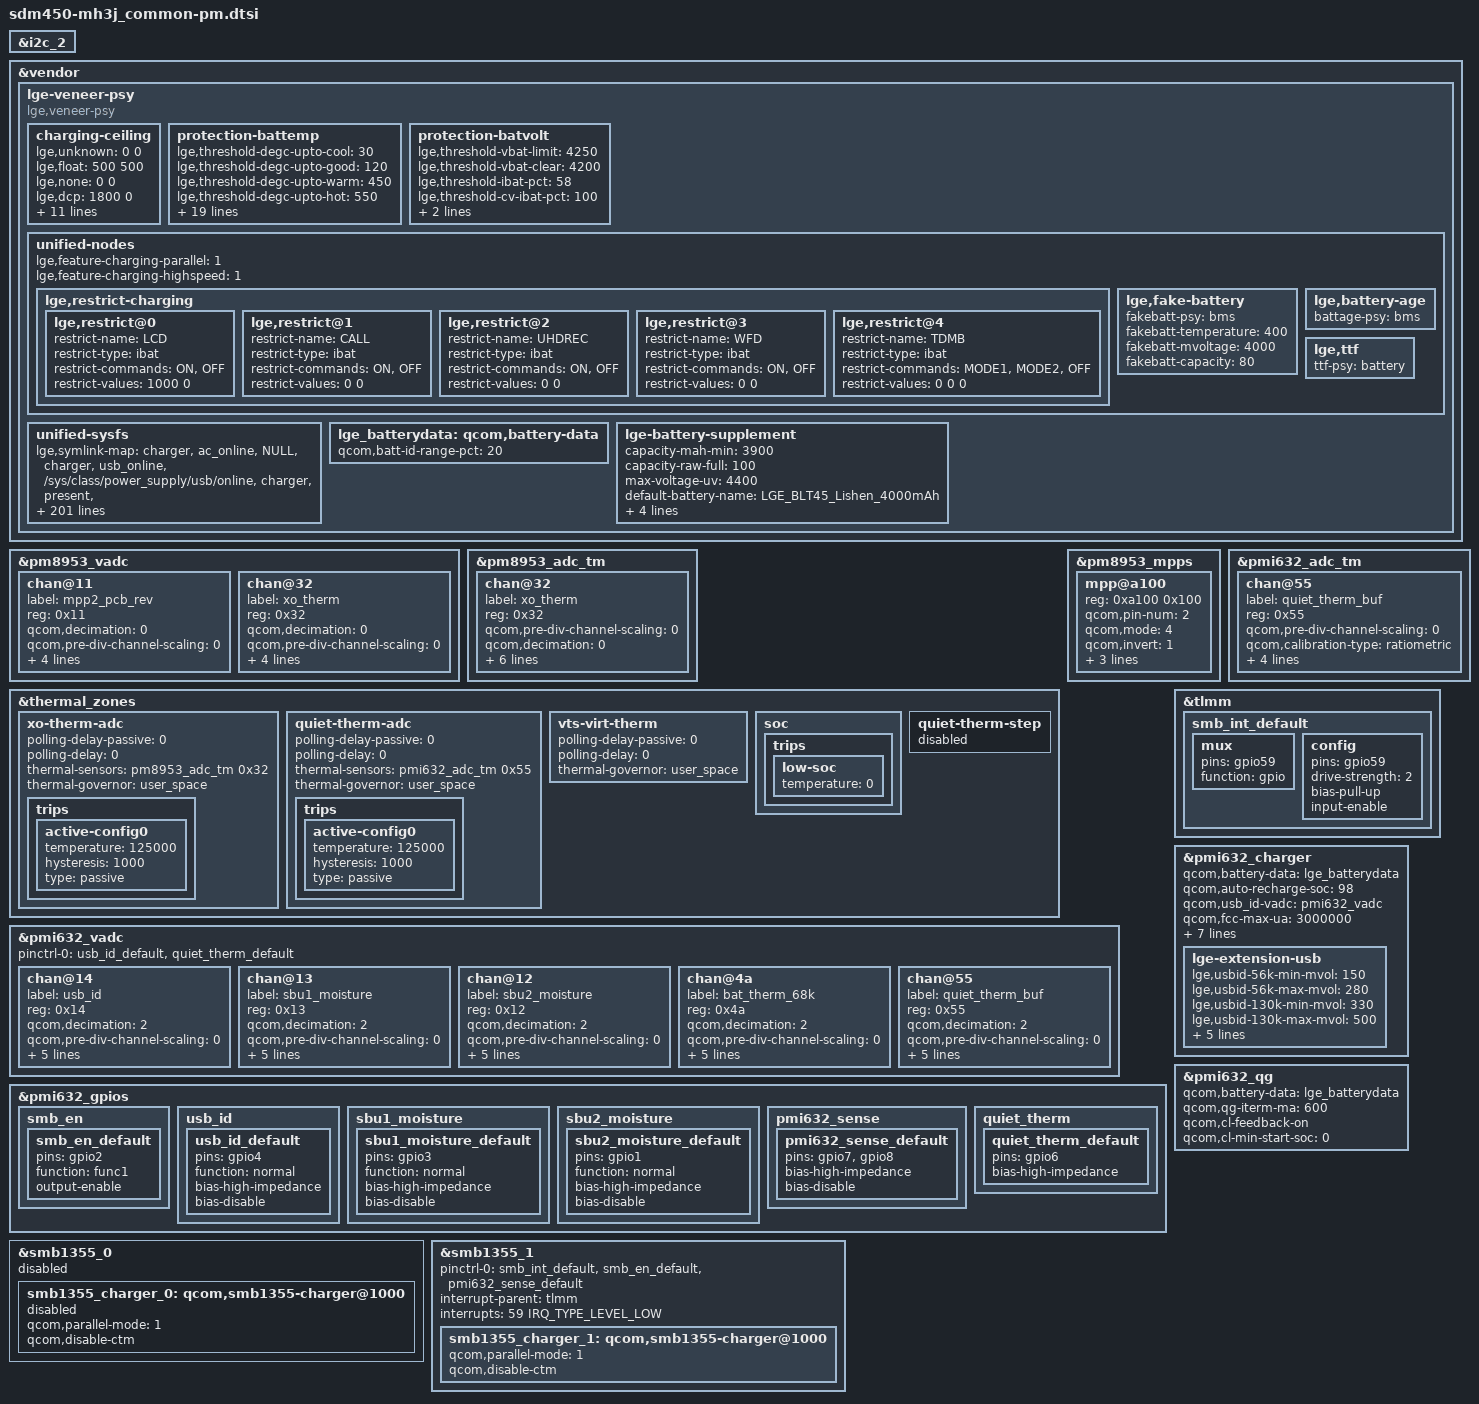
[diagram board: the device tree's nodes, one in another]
/*
 * Copyright (c) 2018, The Linux Foundation. All rights reserved.
 *
 * This program is free software; you can redistribute it and/or modify
 * it under the terms of the GNU General Public License version 2 and
 * only version 2 as published by the Free Software Foundation.
 *
 * This program is distributed in the hope that it will be useful,
 * but WITHOUT ANY WARRANTY; without even the implied warranty of
 * MERCHANTABILITY or FITNESS FOR A PARTICULAR PURPOSE.  See the
 * GNU General Public License for more details.
 */

&i2c_2 {
#include "../../../qcom/smb1355.dtsi"
};

&vendor {
    lge-veneer-psy {
        compatible = "lge,veneer-psy";
        status = "ok";

        charging-ceiling {
            /*             iusb ibat  : 0 means UNCEILING */
            lge,unknown = <   0    0>;
            lge,float   = < 500  500>;
            lge,none    = <   0    0>;

            lge,dcp     = <1800    0>;
            lge,10k     = <3000    0>;
            lge,22k     = <1500    0>;
            lge,qc2     = <1800    0>;
            lge,qc3     = <1800    0>;

            lge,usb2    = < 500    0>;
            lge,usb3    = < 900    0>;
            lge,cdp     = <1500 1500>;
            lge,pd      = <   0    0>;

            lge,56k     = <1500  500>;
            lge,130k    = <1500  500>;
            lge,910k    = <1500  500>;
        };

        protection-battemp {
            lge,threshold-degc-upto-cool = <30>;
            lge,threshold-degc-upto-good = <120>;
            lge,threshold-degc-upto-warm = <450>;
            lge,threshold-degc-upto-hot = <550>;
            lge,threshold-degc-downto-warm = <520>;
            lge,threshold-degc-downto-good = <430>;
            lge,threshold-degc-downto-cool = <100>;
            lge,threshold-degc-downto-cold = <0>;

            lge,period-ms-emergency = <10000>;
            lge,period-ms-warning   = <30000>;
            lge,period-ms-normal    = <60000>;

            // parameters for warning status cool and warm
            lge,cool-mv-alert   = <4000>;
            lge,cool-ma-alert   = <500>;    // fixed 500 mA
            lge,cool-ma-pct     = <30>;     // means 0.3C rate

            lge,warm-mv-float   = <4000>;
            lge,warm-ma-pct     = <30>;     // means 0.3C rate

            // parameters for battery protection at chilly status
            lge,chilly-status-support;
            lge,chilly-degc-lowerbound = <0>;
            lge,chilly-degc-upperbound = <150>;
            lge,chilly-mv-alert    = <4000>;
            lge,chilly-mv-bound     = <200>;
            lge,chilly-ma-alert    = <630>;
            lge,chilly-ma-pct      = <50>;  // means 0.5C rate under batvol 4V
        };

        protection-batvolt {
            lge,threshold-vbat-limit = <4250>;
            lge,threshold-vbat-clear = <4200>;
	    lge,threshold-ibat-pct = <58>;	// means 0.6C rate
	    lge,threshold-cv-ibat-pct = <100>;	// means 0.1C rate

            lge,step-ibat-ma = <100>;
            lge,step-poll-ms = <5000>;
        };

        unified-nodes {
            lge,feature-charging-parallel = <1>;
            lge,feature-charging-highspeed = <1>;

            lge,restrict-charging {
                // restrict-values 0 means UNCEILING

                lge,restrict@0 {
                    restrict-name = "LCD";
                    restrict-type = "ibat";
                    restrict-commands = "ON", "OFF";
                    restrict-values = <1000      0>;
                };
                lge,restrict@1 {
                    restrict-name = "CALL";
                    restrict-type = "ibat";
                    restrict-commands = "ON", "OFF";
                    restrict-values = < 0      0>;
                };
                lge,restrict@2 {
                    restrict-name = "UHDREC";
                    restrict-type = "ibat";
                    restrict-commands = "ON", "OFF";
                    restrict-values = < 0      0>;
                };
                lge,restrict@3 {
                    restrict-name = "WFD";
                    restrict-type = "ibat";
                    restrict-commands = "ON", "OFF";
                    restrict-values = < 0      0>;
                };
                lge,restrict@4 {
                    restrict-name = "TDMB";
                    restrict-type = "ibat";
                    restrict-commands = "MODE1", "MODE2", "OFF";
                    restrict-values = <    0      0      0>;
                };
            };

            lge,fake-battery {
                fakebatt-psy = "bms";       // What 'psy' does implement(or support) the fake battery?
                fakebatt-temperature = <400>;
                fakebatt-mvoltage = <4000>;
                fakebatt-capacity = <80>;
            };

            lge,battery-age {
                battage-psy = "bms";        // What 'psy' does implement(or support) the battery age?
            };

            lge,ttf {
                ttf-psy = "battery";	// What 'psy' does implement(or support) the time to full now?
            };
        };

        unified-sysfs {
            lge,symlink-map =
                /* group , user_node, kernel node */
                /* Charger */
                "charger",                     "ac_online", "NULL",
                "charger",                    "usb_online", "/sys/class/power_supply/usb/online",   /* TODO */
                "charger",                       "present", "/sys/class/power_supply/usb/present",
                "charger",                    "wlc_online", "/sys/class/power_supply/wireless/online",
                "charger",                          "type", "/sys/class/power_supply/usb/real_type",
		"charger",                   "usb_pd_type", "/sys/class/power_supply/usb/real_type",
                "charger",                      "time_out", "/sys/class/power_supply/battery/safety_timer_enabled",
                "charger",              "charging_enabled", "/sys/devices/platform/lge-unified-nodes/charging_enable",
                "charger",                  "ibat_current", "/sys/class/power_supply/battery/current_now",
                "charger",                  "ichg_current", "/sys/class/power_supply/usb/current_max",
                "charger",                  "iusb_control", "NULL",
                "charger",            "thermal_mitigation", "NULL",
                "charger",        "wlc_thermal_mitigation", "NULL",
                "charger",       "usb_parallel_chg_status", "NULL",
                "charger", "usb_parallel_charging_enabled", "/sys/class/power_supply/parallel/charging_enabled",
                "charger", "factory_parallel_charger_test", "/sys/devices/platform/lge-unified-nodes/support_fastpl",
                "charger",            "moisture_detection", "/sys/class/power_supply/usb/moisture_detected",
                "charger",           "restricted_charging", "/sys/devices/platform/lge-unified-nodes/charging_restriction",
                "charger",              "ibat_max_current", "/sys/class/power_supply/battery/constant_charge_current_max",
                "charger",                       "chgstep", "/sys/devices/platform/lge-unified-nodes/charging_step",
                "charger",               "connection_type", "NULL",
                "charger",                       "fastchg", "/sys/devices/platform/lge-unified-nodes/charger_highspeed",
                "charger",         "input_current_settled", "/sys/class/power_supply/usb/input_current_settled",
                "charger",             "input_current_max", "/sys/class/power_supply/usb/input_current_settled",
                "charger",            "store_demo_enabled", "NULL",
                "charger",     "wireless_charging_enabled", "NULL",
                "charger",                 "input_suspend", "/sys/class/power_supply/battery/input_suspend",
                "charger",                  "incompatible", "/sys/devices/platform/lge-unified-nodes/charger_incompatible",
                "charger",                    "hvdcp_fake", "/sys/devices/platform/lge-unified-nodes/fake_hvdcp",
                "charger",               "usb_current_max", "/sys/devices/platform/lge-unified-nodes/fake_sdpmax",
                "charger",               "fastchg_support", "/sys/devices/platform/lge-unified-nodes/support_fastchg",
                "charger",                    "usbid_type", "/sys/class/power_supply/usb/resistance_id",
                "charger",                 "ccd_batchg_en", "/sys/devices/platform/lge-unified-nodes/ccd_batchg_en",
                "charger",             "ccd_input_suspend", "/sys/devices/platform/lge-unified-nodes/ccd_input_suspend",
                "charger",                       "ccd_icl", "/sys/devices/platform/lge-unified-nodes/ccd_icl",
                "charger",                       "ccd_fcc", "/sys/devices/platform/lge-unified-nodes/ccd_fcc",
                "charger",                    "ccd_vfloat", "/sys/devices/platform/lge-unified-nodes/ccd_vfloat",
		"charger",                     "aicl_done", "/sys/devices/platform/lge-unified-nodes/aicl_done",
                /* ADC/MPP */
                "adc",              "thermal", "/sys/class/thermal/",
                "adc",             "xo_therm", "/sys/class/hwmon/hwmon1/device/xo_therm",
                "adc",           "batt_therm", "/sys/class/power_supply/battery/temp",
                "adc",              "batt_id", "/sys/devices/platform/lge-unified-nodes/battery_valid",
                "adc",            "pa_therm0", "/sys/class/hwmon/hwmon1/device/pa_therm0",
                "adc",            "pa_therm1", "NULL",
                "adc",           "quiet_therm","/sys/class/hwmon/hwmon2/device/quiet_therm_buf",
                "adc",               "usb_in", "/sys/class/power_supply/usb/voltage_now",
                "adc",                "vcoin", "/sys/class/hwmon/hwmon2/device/vcoin",
                "adc",              "vph_pwr", "/sys/class/hwmon/hwmon2/device/vph_pwr",
                "adc",               "usb_id", "/sys/devices/platform/lge-unified-nodes/charger_usbid",
                "adc",             "usb_edge", "NULL",
                "adc",                 "pmic", "/sys/class/thermal/thermal_zone2/temp",
                "adc",                  "vts", "/sys/bus/platform/drivers/monitor-thermal/soc:lge,monitor-thermal/vts_temp",
                /* Battery */
                "battery",         "capacity", "/sys/class/power_supply/battery/capacity",
                "battery",           "health", "/sys/class/power_supply/battery/health",
                "battery",          "present", "/sys/class/power_supply/battery/present",
                "battery",      "pseudo_batt", "/sys/devices/platform/lge-unified-nodes/fake_battery",
                "battery",           "status", "/sys/class/power_supply/battery/status",
                "battery",       "status_raw", "NULL",
                "battery",             "temp", "/sys/class/power_supply/battery/temp",
                "battery",    "valid_batt_id", "/sys/devices/platform/lge-unified-nodes/battery_valid",
                "battery",      "voltage_now", "/sys/class/power_supply/battery/voltage_now",
                "battery",          "vzw_chg", "/sys/devices/platform/lge-unified-nodes/charger_verbose",
                "battery",     "raw_capacity", "/sys/class/power_supply/bms/capacity",
                "battery",        "condition", "/sys/devices/platform/lge-unified-nodes/battery_condition",
                "battery",      "battery_age", "/sys/devices/platform/lge-unified-nodes/battery_age",
                "battery","battery_age_level", "/sys/devices/platform/lge-unified-nodes/battery_age",
                "battery",            "cycle", "/sys/class/power_supply/bms/cycle_count",
                "battery",     "battery_type", "/sys/class/power_supply/bms/battery_type",
                "battery",      "charge_full", "/sys/class/power_supply/bms/charge_full",
                "battery",   "charge_now_raw", "/sys/class/power_supply/bms/charge_now_raw",
                "battery",     "ttf_capacity", "/sys/devices/platform/lge-unified-nodes/ttf_capacity",
                "battery", "time_to_full_now", "/sys/devices/platform/lge-unified-nodes/time_to_full_now",
                /* LCD Backlight */
                "lcd",           "brightness", "/sys/class/backlight/panel0-backlight/brightness",
                "lcd",       "max_brightness", "/sys/class/backlight/panel0-backlight/max_brightness",
                "lcd_ex",        "brightness", "NULL",
                "lcd_ex",    "max_brightness", "NULL",
                /* KEY LED */
                "key_led",   "red_brightness", "/sys/class/leds/red/brightness",
                "key_led", "green_brightness", "/sys/class/leds/green/brightness",
                "key_led",  "blue_brightness", "/sys/class/leds/blue/brightness",
                "key_led",  "setting",         "/sys/class/lg_rgb_led/use_patterns/setting",
                /* CPU */
                "cpu",       "cpu_idle_modes", "NULL",
                /* GPU */
                "gpu",                 "busy", "/sys/class/kgsl/kgsl-3d0/gpubusy",
                "gpu",               "gpuclk", "/sys/class/kgsl/kgsl-3d0/gpuclk",
                /* PLATFORM */
                "platform",       "speed_bin", "NULL",
                "platform",         "pvs_bin", "NULL",
                "platform",     "power_state", "/sys/power/autosleep",
                "platform",   "poweron_alarm", "/sys/module/qpnp_rtc/parameters/poweron_alarm",
                "platform",         "pcb_rev", "/sys/class/hwmon/hwmon1/device/mpp2_pcb_rev",
                "platform",       "smpl_boot", "/sys/module/lge_smpl_count/parameters/smpl_boot",
                /* testmode */
                "testmode",            "temp", "/sys/class/power_supply/battery/temp",
                "testmode",     "voltage_now", "/sys/class/power_supply/battery/voltage_now",
                "testmode",          "usb_id", "/sys/devices/platform/lge-unified-nodes/charger_usbid",
                "testmode",         "batt_id", "/sys/devices/platform/lge-unified-nodes/battery_valid",
                "testmode",         "fuelval", "/sys/class/power_supply/battery/capacity",
                "testmode",        "xo_therm", "/sys/class/hwmon/hwmon1/device/xo_therm",
                "testmode",          "charge", "/sys/class/power_supply/battery/battery_charging_enabled",
                "testmode",          "chcomp", "/sys/devices/platform/lge-unified-nodes/charging_completed",
                "testmode",           "usbin", "/sys/class/power_supply/usb/voltage_now",
                "testmode",       "pa_therm0", "/sys/class/hwmon/hwmon1/device/pa_therm0",
                "testmode",       "pa_therm1", "NULL",
                "testmode",       "bd_therm2", "/sys/class/hwmon/hwmon2/device/quiet_therm_buf",
                "testmode",           "vcoin", "/sys/class/hwmon/hwmon2/device/vcoin",
                "testmode",         "vph_pwr", "/sys/class/hwmon/hwmon2/device/vph_pwr",
                "testmode",     "current_now", "/sys/class/power_supply/battery/current_now",
                "testmode",     "current_max", "/sys/class/power_supply/usb/current_max",
                "testmode",         "pcb_rev", "/sys/class/hwmon/hwmon1/device/mpp2_pcb_rev",
                "testmode",      "chgmodeoff", "/sys/class/power_supply/battery/input_suspend",
                "testmode",         "fuelrst", "/sys/class/power_supply/battery/present",
                "testmode",        "rtc_time", "/dev/rtc0",
                "testmode",           "pmrst", "NULL",
                "testmode",        "battexit", "/sys/class/power_supply/battery/present",
                "testmode",  "hardreset_mode", "NULL",
                /* ps feature*/
                "psfeature",     "vfps_ratio", "/sys/class/power/vfps/vfps_ratio",
                "psfeature",           "vfps", "/sys/class/power/vfps/vfps",
                "psfeature",      "vfps_fcnt", "/sys/class/power/vfps/vfps_fcnt",
                "psfeature",  "triton_policy", "/sys/class/power/triton/cur_policy",
                "psfeature",   "cancun_is_cm", "NULL",
                "regulator",       "vreg_bob", "/sys/devices/platform/soc/soc:lrmc/bob_mode";
        };

	lge_batterydata: qcom,battery-data {
			qcom,batt-id-range-pct = <20>;
			#include "../../battery_profile/LGE_BLT45_Lishen_4000mAh.dtsi"
	};


	lge-battery-supplement {
	   capacity-mah-min = <3900>;
	   capacity-raw-full = <100>;
	   max-voltage-uv = <4400>;

	   default-battery-name = "LGE_BLT45_Lishen_4000mAh";
	   default-battery-kohm = <120>;

	/* format : (temp index) (temp delta) */
	   tempcomp-offset = <
	        (-300)    (-7)
	        (-200)    (-7)
	        (-190)    (-7)
	        (-180)    (-7)
	        (-170)    (-7)
	        (-160)    (-7)
	        (-150)    (-7)
	        (-100)    (-7)
	        ( -50)    (-7)
	        0         (-7)
	        50        (-7)
	        100       (-7)
	        150       (-7)
	        200       (-6)
	        250     (-5)
	        300     (-3)
	        350     (-1)
	        400     (1)
	        450     (3)
	        500     (6)
	        550     (9)
	        600     (12)
	        700     (18)
	        800     (24)
	        900     (30)
	        >;
	   tempcomp-icoeff = <114>;

	/* overriding by battery type */
	/*
		LGE_BLT44_Tocad_3450mAh {
	        tempcomp-icoeff = <0>;
	        };
		LGE_BLT44_LGC_3450mAh {
	        tempcomp-icoeff = <0>;
	        };
	*/
	};
    };
};

&pm8953_vadc {
	chan@11 {
		label = "mpp2_pcb_rev";
		reg = <0x11>;
		qcom,decimation = <0>;
		qcom,pre-div-channel-scaling = <0>;
		qcom,calibration-type = "ratiometric";
		qcom,scale-function = <0>;
		qcom,hw-settle-time = <2>;
		qcom,fast-avg-setup = <3>;
	};

	chan@32 {
		label = "xo_therm";
		reg = <0x32>;
		qcom,decimation = <0>;
		qcom,pre-div-channel-scaling = <0>;
		qcom,calibration-type = "ratiometric";
		qcom,scale-function = <4>;
		qcom,hw-settle-time = <2>;
		qcom,fast-avg-setup = <0>;
	};
};

&pm8953_adc_tm {
	chan@32 {
		label = "xo_therm";
		reg = <0x32>;
		qcom,pre-div-channel-scaling = <0>;
		qcom,decimation = <0>;
		qcom,calibration-type = "ratiometric";
		qcom,scale-function = <4>;
		qcom,hw-settle-time = <2>;
		qcom,btm-channel-number = <0x68>;
		qcom,fast-avg-setup = <0>;
		qcom,thermal-node;
	};
};

&thermal_zones {
	xo-therm-adc {
		polling-delay-passive = <0>;
		polling-delay = <0>;
		thermal-sensors = <&pm8953_adc_tm 0x32>;
		thermal-governor = "user_space";

		trips {
			active-config0 {
				temperature = <125000>;
				hysteresis = <1000>;
				type = "passive";
			};
		};
	};

	quiet-therm-adc {
		polling-delay-passive = <0>;
		polling-delay = <0>;
		thermal-sensors = <&pmi632_adc_tm 0x55>;
		thermal-governor = "user_space";

		trips {
			active-config0 {
				temperature = <125000>;
				hysteresis = <1000>;
				type = "passive";
			};
		};
	};

	vts-virt-therm {
		polling-delay-passive = <0>;
		polling-delay = <0>;
		thermal-governor = "user_space";
	};

	soc {
		trips {
			low-soc {
				temperature = <0>;
			};
		};
	};

	quiet-therm-step {
		status = "disabled"; /* Not use quiet-therm mitigation */
	};
};

&pm8953_mpps {
	mpp@a100 {
		reg = <0xa100 0x100>;
		qcom,pin-num = <2>;
		qcom,mode = <4>; /* AIN input */
		qcom,invert = <1>; /* Enable MPP */
		qcom,ain-route = <1>; /* AMUX 6 */
		qcom,master-en = <1>;
		qcom,src-sel = <0>; /* Function constant */
	};
};

&pmi632_vadc {
    pinctrl-names = "default";
    pinctrl-0 = <&usb_id_default &quiet_therm_default>;

    chan@14 {
        label = "usb_id";
        reg = <0x14>;
        qcom,decimation = <2>;
        qcom,pre-div-channel-scaling = <0>;
        qcom,calibration-type = "ratiometric";
        qcom,scale-function = <0>;
        qcom,hw-settle-time = <2>;
        qcom,fast-avg-setup = <0>;
        qcom,cal-val = <0>;
    };

    chan@13 {
        label = "sbu1_moisture";
        reg = <0x13>;
        qcom,decimation = <2>;
        qcom,pre-div-channel-scaling = <0>;
        qcom,calibration-type = "ratiometric";
        qcom,scale-function = <0>;
        qcom,hw-settle-time = <2>;
        qcom,fast-avg-setup = <0>;
        qcom,cal-val = <0>;
    };

    chan@12 {
        label = "sbu2_moisture";
        reg = <0x12>;
        qcom,decimation = <2>;
        qcom,pre-div-channel-scaling = <0>;
        qcom,calibration-type = "ratiometric";
        qcom,scale-function = <0>;
        qcom,hw-settle-time = <2>;
        qcom,fast-avg-setup = <0>;
        qcom,cal-val = <0>;
    };
    
    chan@4a {
        label = "bat_therm_68k";
        reg = <0x4a>;
        qcom,decimation = <2>;
        qcom,pre-div-channel-scaling = <0>;
        qcom,calibration-type = "ratiometric";
        qcom,scale-function = <26>;
        qcom,hw-settle-time = <0xb>;
        qcom,fast-avg-setup = <0>;
        qcom,cal-val = <0>;
    };

    chan@55 {
        label = "quiet_therm_buf";
        reg = <0x55>;
        qcom,decimation = <2>;
        qcom,pre-div-channel-scaling = <0>;
        qcom,calibration-type = "ratiometric";
        qcom,scale-function = <2>;
        qcom,hw-settle-time = <0>;
        qcom,fast-avg-setup = <0>;
        qcom,cal-val = <0>;
    };
};

&pmi632_adc_tm {
    chan@55 {
        label = "quiet_therm_buf";
        reg = <0x55>;
        qcom,pre-div-channel-scaling = <0>;
        qcom,calibration-type = "ratiometric";
        qcom,scale-function = <2>;
        qcom,hw-settle-time = <0>;
        qcom,btm-channel-number = <0x60>;
        qcom,thermal-node;
    };
};

&pmi632_gpios {
        smb_en {
                smb_en_default: smb_en_default {
                        pins = "gpio2";
                        function = "func1";
                        output-enable;
                };
        };

        usb_id {
                usb_id_default: usb_id_default {
                        pins = "gpio4";
                        function = "normal";
                        bias-high-impedance;
                        bias-disable;
                };
        };

        sbu1_moisture {
                sbu1_moisture_default: sbu1_moisture_default {
                        pins = "gpio3";
                        function = "normal";
                        bias-high-impedance;
                        bias-disable;
                };
        };
        
        sbu2_moisture {
                sbu2_moisture_default: sbu2_moisture_default {
                        pins = "gpio1";
                        function = "normal";
                        bias-high-impedance;
                        bias-disable;
                };
        };

        pmi632_sense {
            /* GPIO 7 and 8 are external-sense pins for PMI632 */
                pmi632_sense_default: pmi632_sense_default {
                        pins = "gpio7", "gpio8";
                        bias-high-impedance;    /* disable the GPIO */
                        bias-disable;           /* no-pull */
                };
        };

        quiet_therm {
                quiet_therm_default: quiet_therm_default {
                        pins = "gpio6";
                        bias-high-impedance;
                };
        };
};

&tlmm {
        smb_int_default: smb_int_default {
                     mux {
                         pins = "gpio59";
                         function = "gpio";
                     };
                     config {
                         pins = "gpio59";
                         drive-strength = <2>;
                         bias-pull-up;
                         input-enable;
                     };
        };
};

&pmi632_charger {
    qcom,battery-data = <&lge_batterydata>;
    qcom,auto-recharge-soc = <98>;
    qcom,usb_id-vadc = <&pmi632_vadc>;
    qcom,fcc-max-ua = <3000000>;
    qcom,usb-icl-ua = <1800000>;
    qcom,fv-max-uv = <4400000>;
    qcom,chg-term-src = <1>;
    qcom,chg-term-current-ma = <(-150)>;
    qcom,flash-disable-soc = <5>;
    lge,parallel-pct = <50>;
    qcom,hvdcp-disable;

    lge-extension-usb {
		lge,usbid-56k-min-mvol = <150>;
		lge,usbid-56k-max-mvol = <280>;
		lge,usbid-130k-min-mvol = <330>;
		lge,usbid-130k-max-mvol = <500>;
		lge,usbid-910k-min-mvol = <750>;
		lge,usbid-910k-max-mvol = <900>;
		lge,usbid-open-min-mvol = <950>;
		lge,usbid-open-max-mvol = <1100>;
        lge,feature-moisture-charging = <0>;
    };
};

&pmi632_qg {
    qcom,battery-data = <&lge_batterydata>;
    qcom,qg-iterm-ma = <600>;
    qcom,cl-feedback-on;
    qcom,cl-min-start-soc = <0>;
};

&smb1355_0 {
    /delete-property/ interrupt-parent;
    /delete-property/ interrupts;
    /delete-property/ interrupt-controller;
    status = "disabled";
    smb1355_charger_0: qcom,smb1355-charger@1000  {
		status ="disabled";
		/delete-property/ io-channels;
		/delete-property/ io-channels-names;
		qcom,parallel-mode = <1>;
		qcom,disable-ctm;
	};
};


&smb1355_1 {
    pinctrl-names = "default";
    pinctrl-0 = <&smb_int_default
        &smb_en_default &pmi632_sense_default>;
    interrupt-parent = <&tlmm>;
    interrupts = <59 IRQ_TYPE_LEVEL_LOW>;
    status = "ok";
	smb1355_charger_1: qcom,smb1355-charger@1000 {
		status ="ok";
		/delete-property/ io-channels;
		/delete-property/ io-channels-names;
		qcom,parallel-mode = <1>;
		qcom,disable-ctm;
	};
};
